VERSION ""

NS_ :

BS_:

BU_: GPU_F MM5_10 PTU GPU TMU_RR TMU_RL TMU_FR TMU_FL DMI SMU_F SMU_R MS6 SW TCU PDU Logger TKU
VAL_TABLE_ BSPD_Emergency 1 "BSPD OK" 0 "Emergancy Open " ;

BO_ 3221225472 VECTOR__INDEPENDENT_SIG_MSG: 0 Vector__XXX
 SG_ HBat_V14 : 0|9@1+ (0.01,0) [0|4.5] "V" Vector__XXX
 SG_ HBat_V05 : 0|9@1+ (0.01,0) [0|4.5] "V" Vector__XXX
 SG_ HBat_V04 : 0|9@1+ (0.01,0) [0|4.5] "V" Vector__XXX
 SG_ HBat_V03 : 0|9@1+ (0.01,0) [0|4.5] "V" Vector__XXX
 SG_ HBat_V13 : 0|9@1+ (0.01,0) [0|4.5] "V" Vector__XXX
 SG_ HBat_V12 : 0|9@1+ (0.01,0) [0|4.5] "V" Vector__XXX
 SG_ HBat_V10 : 0|9@1+ (0.01,0) [0|4.5] "V" Vector__XXX
 SG_ HBat_V11 : 0|9@1+ (0.01,0) [0|4.5] "V" Vector__XXX
 SG_ HBat_V09 : 0|9@1+ (0.01,0) [0|4.5] "V" Vector__XXX
 SG_ HBat_V08 : 0|9@1+ (0.01,0) [0|4.5] "V" Vector__XXX
 SG_ HBat_V07 : 0|9@1+ (0.01,0) [0|4.5] "V" Vector__XXX
 SG_ HBat_V06 : 0|9@1+ (0.01,0) [0|4.5] "V" Vector__XXX
 SG_ HBat_V02 : 0|9@1+ (0.01,0) [0|4.5] "V" Vector__XXX
 SG_ HBat_V01 : 0|9@1+ (0.01,0) [0|4.5] "V" Vector__XXX

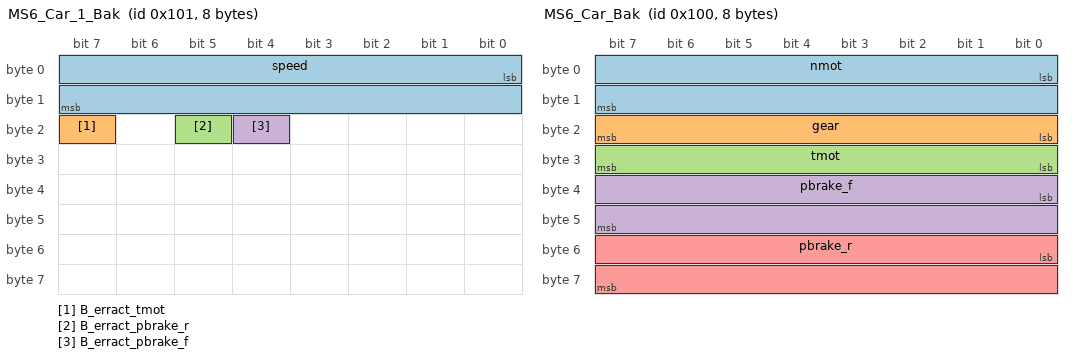
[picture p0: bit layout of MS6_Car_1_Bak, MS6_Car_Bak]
BO_ 257 MS6_Car_1_Bak: 8 MS6
 SG_ speed : 0|16@1+ (0.01,0) [0|400] "km/h"  Logger
 SG_ B_erract_tmot : 23|1@1+ (1,0) [0|1] ""  Logger
 SG_ B_erract_pbrake_r : 21|1@1+ (1,0) [0|1] ""  Logger
 SG_ B_erract_pbrake_f : 20|1@1+ (1,0) [0|1] ""  Logger

BO_ 256 MS6_Car_Bak: 8 MS6
 SG_ nmot : 0|16@1+ (1,0) [0|20000] "rpm"  Logger
 SG_ gear : 16|8@1+ (1,0) [-1|12] ""  Logger
 SG_ tmot : 24|8@1+ (1,-40) [40|120] "°C"  Logger
 SG_ pbrake_f : 32|16@1+ (0.005,0) [0|150] "bar"  Logger
 SG_ pbrake_r : 48|16@1+ (0.005,0) [0|150] "bar"  Logger

BO_ 1120 SMU_R_SpringDeflection: 5 SMU_R
 SG_ SpringDeflectionRR : 16|12@1+ (0.0193,0) [0|79.0335] ""  Logger
 SG_ SpringDeflectionRL : 0|12@1+ (0.0193,0) [0|79.0335] ""  Logger

BO_ 1856 GPU_State: 8 GPU
 SG_ Error_GPU : 8|8@1+ (1,0) [0|0] ""  Logger
 SG_ Alive_GPU : 0|8@1+ (1,0) [0|255] ""  Logger

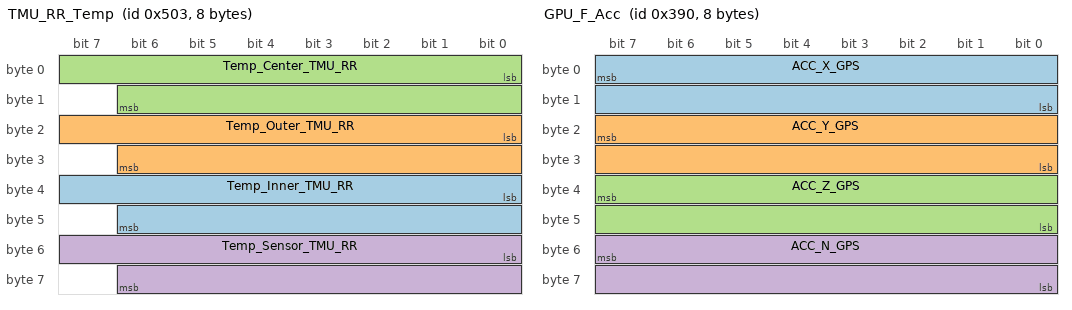
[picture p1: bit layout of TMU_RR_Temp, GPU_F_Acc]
BO_ 1283 TMU_RR_Temp: 8 TMU_RR
 SG_ Temp_Inner_TMU_RR : 32|15@1+ (0.02,-273.15) [-40|85] "°C"  Logger
 SG_ Temp_Outer_TMU_RR : 16|15@1+ (0.02,-273.15) [-40|85] "°C"  Logger
 SG_ Temp_Center_TMU_RR : 0|15@1+ (0.02,-273.15) [-40|85] "°C"  Logger
 SG_ Temp_Sensor_TMU_RR : 48|15@1+ (0.02,-273.15) [-40|125] "°C"  Logger

BO_ 912 GPU_F_Acc: 8 GPU_F
 SG_ ACC_X_GPS : 7|16@0+ (0.0025,-81.9175) [0|0] "m/s"  GPU_F
 SG_ ACC_Y_GPS : 23|16@0+ (0.0025,-81.9175) [0|0] "m/s"  GPU_F
 SG_ ACC_Z_GPS : 39|16@0+ (0.0025,-81.9175) [0|0] "m/s"  GPU_F
 SG_ ACC_N_GPS : 55|16@0+ (0.0025,0) [0|0] "m/s"  GPU_F

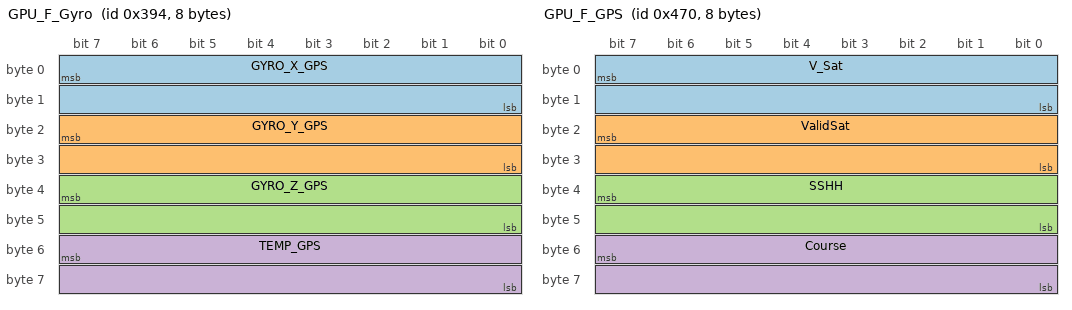
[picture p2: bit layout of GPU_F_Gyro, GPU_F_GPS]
BO_ 916 GPU_F_Gyro: 8 GPU_F
 SG_ GYRO_X_GPS : 7|16@0+ (0.08,-2621.36) [0|0] "deg/s"  GPU_F
 SG_ GYRO_Y_GPS : 23|16@0+ (0.08,-2621.36) [0|0] "deg/s"  GPU_F
 SG_ GYRO_Z_GPS : 39|16@0+ (0.08,-2621.36) [0|0] "deg/s"  GPU_F
 SG_ TEMP_GPS : 55|16@0- (0.1,0) [0|0] "°C"  GPU_F

BO_ 1136 GPU_F_GPS: 8 GPU_F
 SG_ V_Sat : 7|16@0+ (0.01,0) [0|0] "km/h"  GPU_F
 SG_ ValidSat : 23|16@0+ (0.0001,0) [0|0] ""  GPU_F
 SG_ SSHH : 39|16@0+ (0.01,0) [0|0] ""  GPU_F
 SG_ Course : 55|16@0+ (0.01,0) [0|0] "deg"  GPU_F

BO_ 1140 GPU_F_Pos: 8 GPU_F
 SG_ Lat_dez : 7|32@0+ (1E-007,0) [0|0] "deg"  GPU_F
 SG_ Lon_dez : 39|32@0+ (1E-007,0) [0|0] "deg"  GPU_F

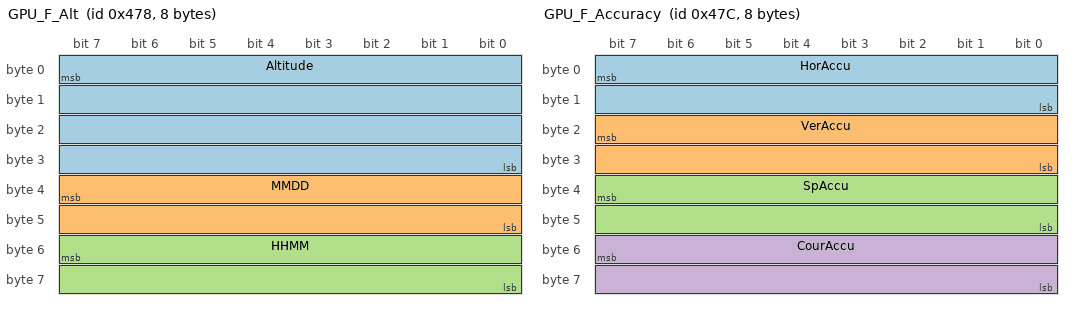
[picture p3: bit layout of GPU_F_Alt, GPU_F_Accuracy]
BO_ 1144 GPU_F_Alt: 8 GPU_F
 SG_ Altitude : 7|32@0+ (0.01,0) [0|0] "m"  GPU_F
 SG_ MMDD : 39|16@0+ (0.01,0) [0|0] ""  GPU_F
 SG_ HHMM : 55|16@0+ (0.01,0) [0|0] ""  GPU_F

BO_ 1148 GPU_F_Accuracy: 8 GPU_F
 SG_ HorAccu : 7|16@0+ (0.001,0) [0|0] "m"  GPU_F
 SG_ VerAccu : 23|16@0+ (0.001,0) [0|0] "m"  GPU_F
 SG_ SpAccu : 39|16@0+ (0.036,0) [0|0] "km/h"  GPU_F
 SG_ CourAccu : 55|16@0+ (0.01,0) [0|0] "deg"  GPU_F

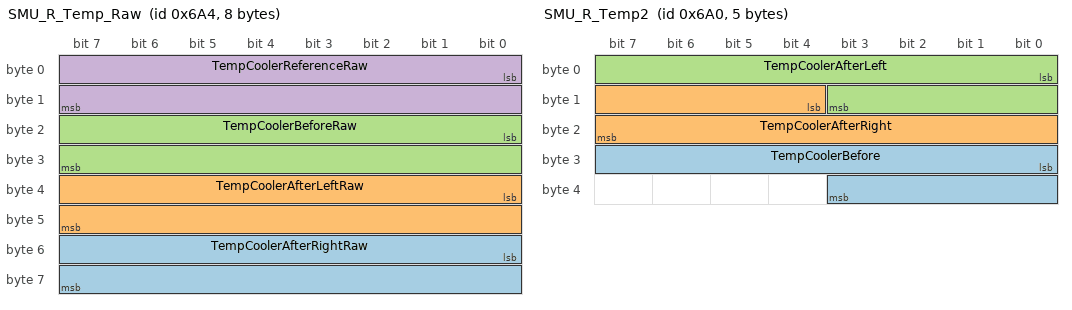
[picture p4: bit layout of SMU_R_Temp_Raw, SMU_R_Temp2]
BO_ 1700 SMU_R_Temp_Raw: 8 SMU_R
 SG_ TempCoolerAfterRightRaw : 48|16@1+ (1,0) [0|65535] ""  Logger
 SG_ TempCoolerAfterLeftRaw : 32|16@1+ (1,0) [0|65535] ""  Logger
 SG_ TempCoolerBeforeRaw : 16|16@1+ (1,0) [0|65535] ""  Logger
 SG_ TempCoolerReferenceRaw : 0|16@1+ (1,0) [0|65535] ""  Logger

BO_ 1696 SMU_R_Temp2: 5 SMU_R
 SG_ TempCoolerBefore : 24|12@1+ (0.1,0) [0|409.5] "°C"  Logger
 SG_ TempCoolerAfterRight : 12|12@1+ (0.1,0) [0|409.5] "°C"  Logger
 SG_ TempCoolerAfterLeft : 0|12@1+ (0.1,0) [0|409.5] "°C"  Logger

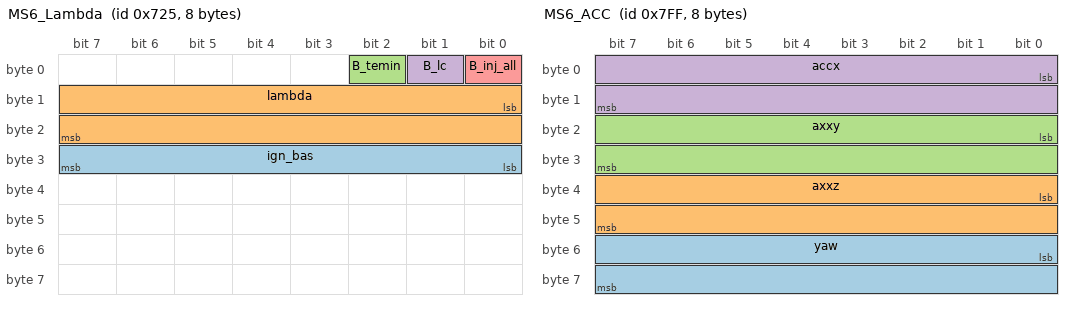
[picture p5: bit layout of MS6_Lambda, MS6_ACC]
BO_ 1829 MS6_Lambda: 8 MS6
 SG_ ign_bas : 24|8@1- (0.5,0) [-30|60] "°CR"  MS6
 SG_ lambda : 8|16@1+ (0.01,0) [0|5] ""  MS6
 SG_ B_temin : 2|1@1+ (1,0) [0|1] ""  Logger
 SG_ B_lc : 1|1@1+ (1,0) [0|1] ""  Logger
 SG_ B_inj_all : 0|1@1+ (1,0) [0|1] ""  Logger

BO_ 1804 MS6_Dist: 8 MS6
 SG_ disttrip : 16|16@1+ (1,0) [0|65535] "km"  Logger
 SG_ ltdist : 0|16@1+ (1,0) [0|65535] "km"  Logger

BO_ 2047 MS6_ACC: 8 MS6
 SG_ yaw : 48|16@1- (0.01,0) [-100|100] "deg/sec"  Logger
 SG_ axxz : 32|16@1- (0.001,0) [-3|3] "g"  Logger
 SG_ axxy : 16|16@1- (0.001,0) [-3|3] "g"  Logger
 SG_ accx : 0|16@1- (0.001,0) [-3|3] "g"  Logger

BO_ 1296 SMU_F_Laptime_Data: 5 SMU_F
 SG_ LapTimePrevious : 8|32@1+ (0.001,0) [0|4294967.295] "s"  DMI,Logger
 SG_ LapCount : 0|8@1+ (1,0) [0|255] ""  DMI,Logger

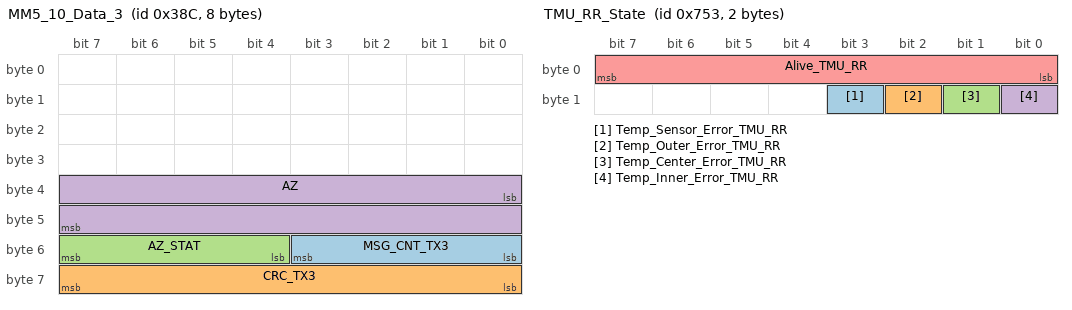
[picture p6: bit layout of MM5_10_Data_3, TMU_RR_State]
BO_ 908 MM5_10_Data_3: 8 MM5_10
 SG_ MSG_CNT_TX3 : 48|4@1+ (1,0) [0|0] "" Vector__XXX
 SG_ CRC_TX3 : 56|8@1+ (1,0) [0|0] "" Vector__XXX
 SG_ AZ_STAT : 52|4@1+ (1,0) [0|0] "" Vector__XXX
 SG_ AZ : 32|16@1+ (0.000127465,-4.1768) [-4.1768|4.1765] "g" Vector__XXX

BO_ 1846 SMU_R_State: 2 SMU_R
 SG_ Error_SMU_R : 8|8@1+ (1,0) [0|255] ""  Logger
 SG_ Alive_SMU_R : 0|8@1+ (1,0) [0|255] ""  Logger

BO_ 1875 TMU_RR_State: 2 TMU_RR
 SG_ Temp_Sensor_Error_TMU_RR : 11|1@1+ (1,0) [0|1] ""  Logger
 SG_ Temp_Outer_Error_TMU_RR : 10|1@1+ (1,0) [0|1] ""  Logger
 SG_ Temp_Center_Error_TMU_RR : 9|1@1+ (1,0) [0|1] ""  Logger
 SG_ Temp_Inner_Error_TMU_RR : 8|1@1+ (1,0) [0|1] ""  Logger
 SG_ Alive_TMU_RR : 0|8@1+ (1,0) [0|255] ""  Logger

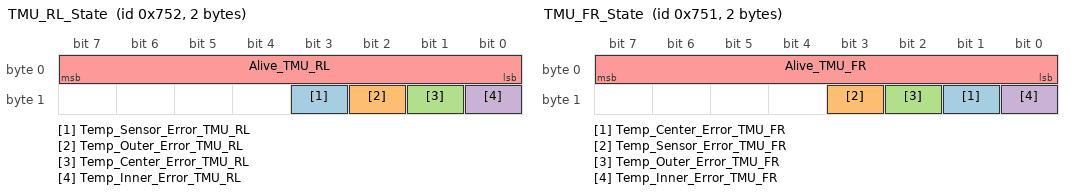
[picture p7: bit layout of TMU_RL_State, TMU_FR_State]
BO_ 1874 TMU_RL_State: 2 TMU_RL
 SG_ Temp_Sensor_Error_TMU_RL : 11|1@1+ (1,0) [0|1] ""  Logger
 SG_ Temp_Outer_Error_TMU_RL : 10|1@1+ (1,0) [0|1] ""  Logger
 SG_ Temp_Center_Error_TMU_RL : 9|1@1+ (1,0) [0|1] ""  Logger
 SG_ Temp_Inner_Error_TMU_RL : 8|1@1+ (1,0) [0|1] ""  Logger
 SG_ Alive_TMU_RL : 0|8@1+ (1,0) [0|255] ""  Logger

BO_ 1873 TMU_FR_State: 2 TMU_FR
 SG_ Temp_Center_Error_TMU_FR : 9|1@1+ (1,0) [0|1] ""  Logger
 SG_ Temp_Sensor_Error_TMU_FR : 11|1@1+ (1,0) [0|1] ""  Logger
 SG_ Temp_Outer_Error_TMU_FR : 10|1@1+ (1,0) [0|1] ""  Logger
 SG_ Temp_Inner_Error_TMU_FR : 8|1@1+ (1,0) [0|1] ""  Logger
 SG_ Alive_TMU_FR : 0|8@1+ (1,0) [0|255] "" Vector__XXX

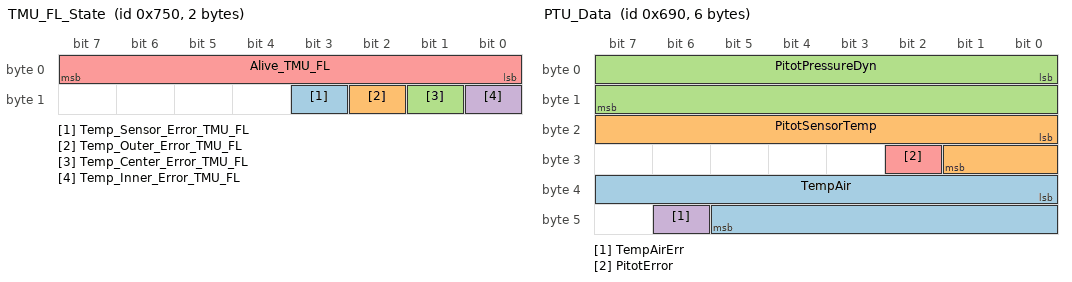
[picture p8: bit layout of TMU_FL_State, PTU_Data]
BO_ 1872 TMU_FL_State: 2 TMU_FL
 SG_ Temp_Sensor_Error_TMU_FL : 11|1@1+ (1,0) [0|1] ""  Logger
 SG_ Temp_Outer_Error_TMU_FL : 10|1@1+ (1,0) [0|1] ""  Logger
 SG_ Temp_Center_Error_TMU_FL : 9|1@1+ (1,0) [0|1] ""  Logger
 SG_ Temp_Inner_Error_TMU_FL : 8|1@1+ (1,0) [0|1] ""  Logger
 SG_ Alive_TMU_FL : 0|8@1+ (1,0) [0|255] ""  Logger

BO_ 1680 PTU_Data: 6 PTU
 SG_ TempAir : 32|14@1- (0.25,0) [-250|1600] "°C"  Logger
 SG_ PitotSensorTemp : 16|10@1+ (0.1956,-50) [-50|150] "°C"  Logger
 SG_ PitotPressureDyn : 0|16@1- (0.2105,0) [-6895|6895] "Pa"  Logger
 SG_ TempAirErr : 46|1@1+ (1,0) [0|1] ""  Logger
 SG_ PitotError : 26|1@1+ (1,0) [0|1] ""  Logger

BO_ 1857 PTU_State: 2 PTU
 SG_ Error_PTU : 8|8@1+ (1,0) [0|255] ""  Logger
 SG_ Alive_PTU : 0|8@1+ (1,0) [0|255] ""  Logger

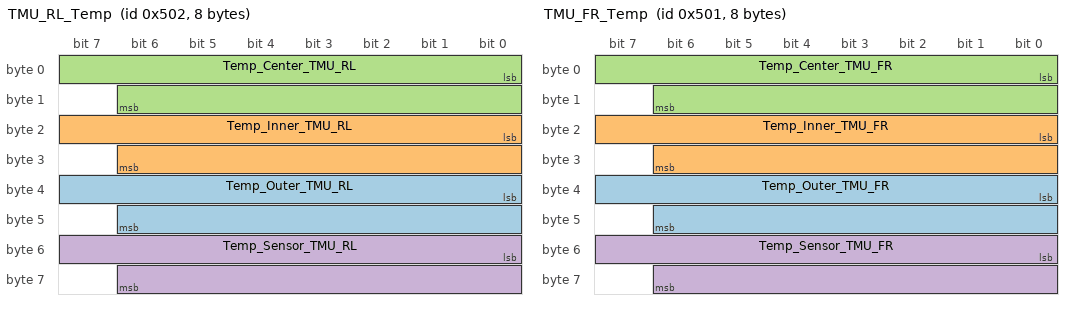
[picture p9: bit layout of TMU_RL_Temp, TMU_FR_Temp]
BO_ 1282 TMU_RL_Temp: 8 TMU_RL
 SG_ Temp_Outer_TMU_RL : 32|15@1+ (0.02,-273.15) [-40|85] "°C"  Logger
 SG_ Temp_Inner_TMU_RL : 16|15@1+ (0.02,-273.15) [-40|85] "°C"  Logger
 SG_ Temp_Center_TMU_RL : 0|15@1+ (0.02,-273.15) [-40|85] "°C"  Logger
 SG_ Temp_Sensor_TMU_RL : 48|15@1+ (0.02,-273.15) [-40|125] "°C"  Logger

BO_ 1281 TMU_FR_Temp: 8 TMU_FR
 SG_ Temp_Outer_TMU_FR : 32|15@1+ (0.02,-273.15) [-40|85] "°C"  Logger
 SG_ Temp_Inner_TMU_FR : 16|15@1+ (0.02,-273.15) [-40|85] "°C"  Logger
 SG_ Temp_Center_TMU_FR : 0|15@1+ (0.02,-273.15) [-40|85] "°C"  Logger
 SG_ Temp_Sensor_TMU_FR : 48|15@1+ (0.02,-273.15) [-40|125] "°C"  Logger

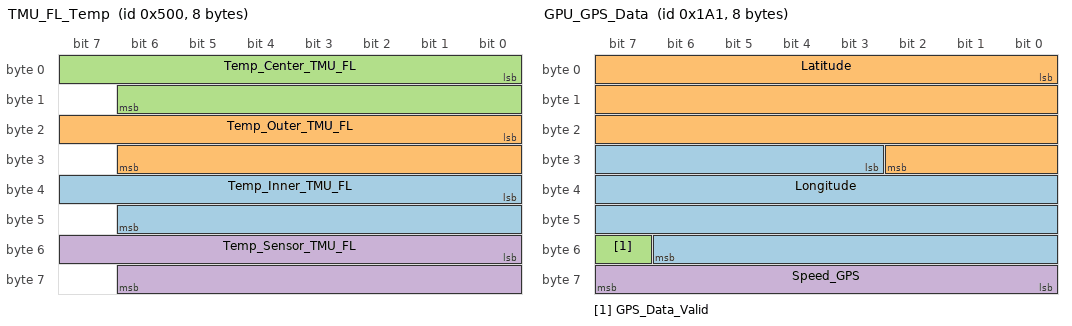
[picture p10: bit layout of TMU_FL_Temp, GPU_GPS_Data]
BO_ 1280 TMU_FL_Temp: 8 TMU_FL
 SG_ Temp_Inner_TMU_FL : 32|15@1+ (0.02,-273.15) [-40|85] "°C"  Logger
 SG_ Temp_Outer_TMU_FL : 16|15@1+ (0.02,-273.15) [-40|85] "°C"  Logger
 SG_ Temp_Center_TMU_FL : 0|15@1+ (0.02,-273.15) [-40|85] "°C"  Logger
 SG_ Temp_Sensor_TMU_FL : 48|15@1+ (0.02,-273.15) [-40|125] "°C"  Logger

BO_ 417 GPU_GPS_Data: 8 GPU
 SG_ Longitude : 27|28@1- (1.6666666667E-006,0) [-180|180] "°"  Logger
 SG_ Latitude : 0|27@1- (1.6666666667E-006,0) [-90|90] "°"  Logger
 SG_ GPS_Data_Valid : 55|1@1+ (1,0) [0|1] ""  Logger
 SG_ Speed_GPS : 56|8@1- (1,0) [-128|127] "km/h"  Logger

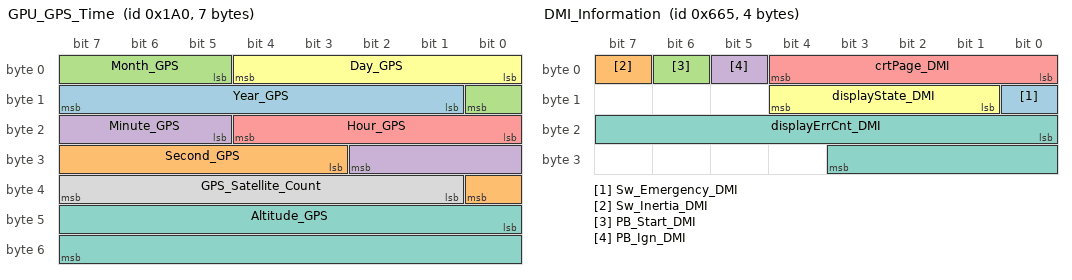
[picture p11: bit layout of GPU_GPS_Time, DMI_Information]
BO_ 416 GPU_GPS_Time: 7 GPU
 SG_ Year_GPS : 9|7@1+ (1,0) [0|99] ""  Logger
 SG_ Second_GPS : 27|6@1+ (1,0) [0|59] ""  Logger
 SG_ Month_GPS : 5|4@1+ (1,0) [0|12] ""  Logger
 SG_ Minute_GPS : 21|6@1+ (1,0) [0|59] ""  Logger
 SG_ Hour_GPS : 16|5@1+ (1,0) [0|23] ""  Logger
 SG_ Day_GPS : 0|5@1+ (1,0) [0|31] ""  Logger
 SG_ Altitude_GPS : 40|16@1+ (1,-999) [-999|3276.7] ""  Logger
 SG_ GPS_Satellite_Count : 33|7@1+ (1,0) [0|127] ""  Logger

BO_ 1637 DMI_Information: 4 DMI
 SG_ Sw_Emergency_DMI : 8|1@1+ (1,0) [0|1] ""  Logger
 SG_ Sw_Inertia_DMI : 7|1@1+ (1,0) [0|1] ""  Logger
 SG_ PB_Start_DMI : 6|1@1+ (1,0) [0|1] ""  Logger
 SG_ PB_Ign_DMI : 5|1@1+ (1,0) [0|1] ""  Logger
 SG_ crtPage_DMI : 0|5@1+ (1,0) [0|31] ""  Logger
 SG_ displayState_DMI : 9|4@1+ (1,0) [0|15] "" Vector__XXX
 SG_ displayErrCnt_DMI : 16|12@1+ (1,0) [0|4095] "" Vector__XXX

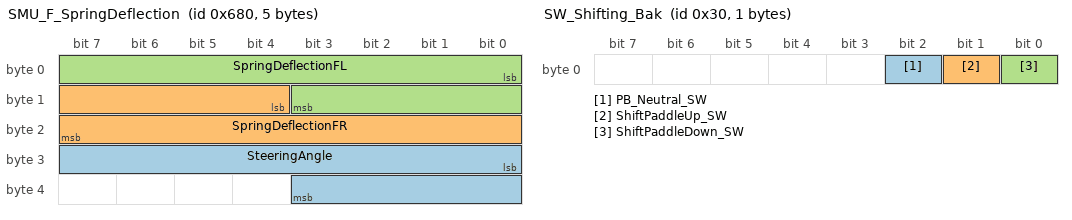
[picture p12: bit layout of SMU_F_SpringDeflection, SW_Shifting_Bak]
BO_ 1664 SMU_F_SpringDeflection: 5 SMU_F
 SG_ SteeringAngle : 24|12@1+ (0.24415,-233.33) [-233.33|766.46425] ""  Logger
 SG_ SpringDeflectionFR : 12|12@1+ (0.018315018,0) [0|74.99999871] ""  Logger
 SG_ SpringDeflectionFL : 0|12@1+ (0.018315018,0) [0|74.99999871] ""  Logger

BO_ 48 SW_Shifting_Bak: 1 SW
 SG_ PB_Neutral_SW : 2|1@1+ (1,0) [0|1] ""  Logger
 SG_ ShiftPaddleUp_SW : 1|1@1+ (1,0) [0|1] ""  Logger,TCU
 SG_ ShiftPaddleDown_SW : 0|1@1+ (1,0) [0|1] ""  Logger,TCU

BO_ 64 SW_Clutch_Bak: 2 SW
 SG_ ClutchPercentRight_SW : 8|8@1+ (0.3922,0) [0|100] "%"  Logger,TCU
 SG_ ClutchPercentLeft_SW : 0|8@1+ (0.3922,0) [0|100] "%"  Logger,TCU

BO_ 1845 DMI_State: 2 DMI
 SG_ Error_DMI : 8|8@1+ (1,0) [0|0] ""  Logger
 SG_ Alive_DMI : 0|8@1+ (1,0) [0|255] ""  Logger

BO_ 1844 SMU_F_State: 2 SMU_F
 SG_ Error_SMU_F : 8|8@1+ (1,0) [0|0] ""  Logger
 SG_ Alive_SMU_F : 0|8@1+ (1,0) [0|255] ""  Logger

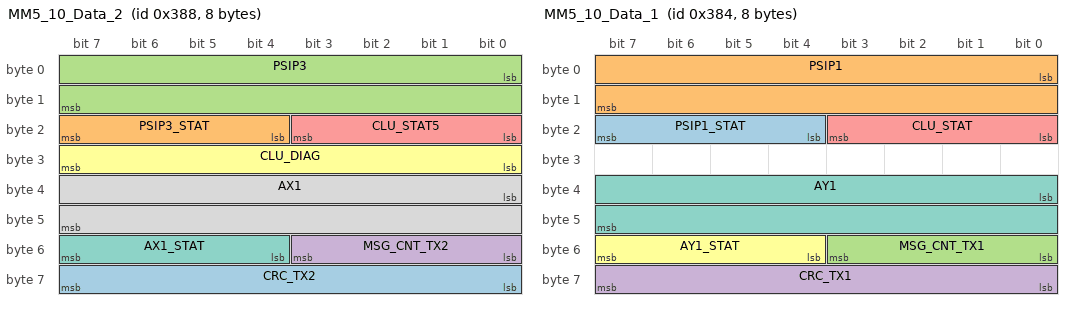
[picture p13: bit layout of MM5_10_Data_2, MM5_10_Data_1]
BO_ 904 MM5_10_Data_2: 8 MM5_10
 SG_ CRC_TX2 : 56|8@1+ (1,0) [0|0] "" Vector__XXX
 SG_ PSIP3_STAT : 20|4@1+ (1,0) [0|0] "" Vector__XXX
 SG_ PSIP3 : 0|16@1+ (0.005,-163.84) [-163.84|163.835] "°/s" Vector__XXX
 SG_ MSG_CNT_TX2 : 48|4@1+ (1,0) [0|0] "" Vector__XXX
 SG_ CLU_STAT5 : 16|4@1+ (1,0) [0|0] "" Vector__XXX
 SG_ CLU_DIAG : 24|8@1+ (1,0) [0|0] "" Vector__XXX
 SG_ AX1_STAT : 52|4@1+ (1,0) [0|0] "" Vector__XXX
 SG_ AX1 : 32|16@1+ (0.000127465,-4.1768) [-4.1768|4.1765] "g" Vector__XXX

BO_ 900 MM5_10_Data_1: 8 MM5_10
 SG_ PSIP1_STAT : 20|4@1+ (1,0) [0|0] "" Vector__XXX
 SG_ PSIP1 : 0|16@1+ (0.005,-163.84) [-163.84|163.83] "°/s" Vector__XXX
 SG_ MSG_CNT_TX1 : 48|4@1+ (1,0) [0|0] "" Vector__XXX
 SG_ CRC_TX1 : 56|8@1+ (1,0) [0|0] "" Vector__XXX
 SG_ CLU_STAT : 16|4@1+ (1,0) [0|0] "" Vector__XXX
 SG_ AY1_STAT : 52|4@1+ (1,0) [0|0] "" Vector__XXX
 SG_ AY1 : 32|16@1+ (0.000127465,-4.1768) [-4.1768|4.1765] "g" Vector__XXX

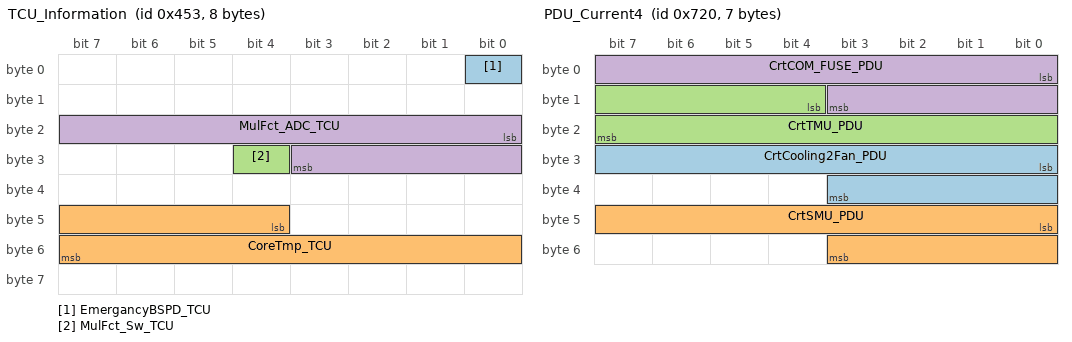
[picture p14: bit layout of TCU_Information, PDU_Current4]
BO_ 1107 TCU_Information: 8 TCU
 SG_ EmergancyBSPD_TCU : 0|1@1+ (1,0) [0|1] "" Vector__XXX
 SG_ CoreTmp_TCU : 44|12@1+ (1,0) [0|0] "°C"  Logger
 SG_ MulFct_Sw_TCU : 28|1@1+ (1,0) [0|1] ""  Logger
 SG_ MulFct_ADC_TCU : 16|12@1+ (1,0) [0|4095] ""  Logger

BO_ 1840 TCU_State: 4 TCU
 SG_ Alive_TCU : 16|8@1+ (1,0) [0|255] ""  Logger
 SG_ Error_TCU : 8|8@1+ (1,0) [0|0] ""  Logger

BO_ 1824 PDU_Current4: 7 PDU
 SG_ CrtCooling2Fan_PDU : 24|12@1+ (13,0) [0|50000] "mA"  Logger
 SG_ CrtSMU_PDU : 40|12@1+ (13,0) [0|50000] "mA" Vector__XXX
 SG_ CrtTMU_PDU : 12|12@1+ (13,0) [0|50000] "mA"  Logger
 SG_ CrtCOM_FUSE_PDU : 0|12@1+ (13,0) [0|50000] "mA"  Logger

BO_ 1842 PDU_State: 2 PDU
 SG_ Error_PDU : 8|8@1+ (1,0) [0|0] ""  Logger
 SG_ Alive_PDU : 0|8@1+ (1,0) [0|255] ""  Logger

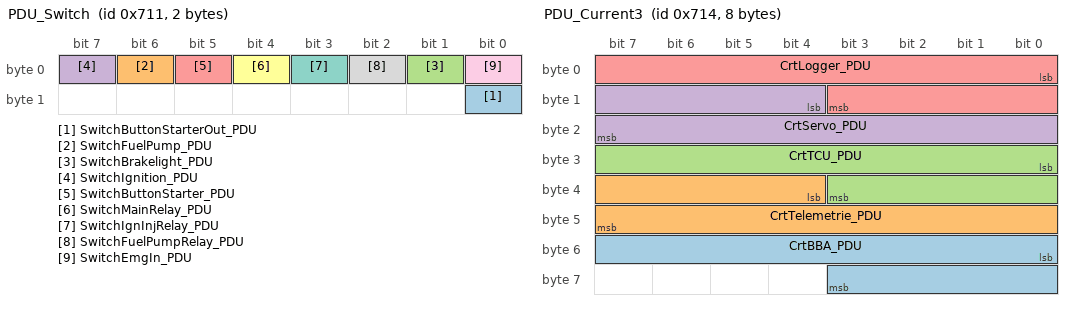
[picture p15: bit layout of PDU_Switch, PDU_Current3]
BO_ 1809 PDU_Switch: 2 PDU
 SG_ SwitchButtonStarterOut_PDU : 8|1@1+ (1,0) [0|1] "Bit"  Logger
 SG_ SwitchFuelPump_PDU : 6|1@1+ (1,0) [0|1] "Bit"  Logger
 SG_ SwitchBrakelight_PDU : 1|1@1+ (1,0) [0|1] "Bit"  Logger
 SG_ SwitchIgnition_PDU : 7|1@1+ (1,0) [0|1] "Bit"  Logger
 SG_ SwitchButtonStarter_PDU : 5|1@1+ (1,0) [0|1] "Bit"  Logger
 SG_ SwitchMainRelay_PDU : 4|1@1+ (1,0) [0|1] "Bit"  Logger
 SG_ SwitchIgnInjRelay_PDU : 3|1@1+ (1,0) [0|1] "Bit"  Logger
 SG_ SwitchFuelPumpRelay_PDU : 2|1@1+ (1,0) [0|1] "Bit"  Logger
 SG_ SwitchEmgIn_PDU : 0|1@1+ (1,0) [0|1] "Bit"  Logger

BO_ 1808 PDU_Fuses: 3 PDU
 SG_ FuseCooling2_PDU : 22|1@1+ (1,0) [0|1] "Bit"  Logger
 SG_ FuseSMU_PDU : 23|1@1+ (1,0) [0|1] "Bit" Vector__XXX
 SG_ FuseBBA_PDU : 14|1@1+ (1,0) [0|1] "Bit"  Logger
 SG_ FuseBSPD_PDU : 13|1@1+ (1,0) [0|1] "Bit"  Logger
 SG_ FuseSwitch_PDU : 3|1@1+ (1,0) [0|1] "Bit"  Logger
 SG_ FuseWaterpump_PDU : 21|1@1+ (1,0) [0|1] "Bit"  Logger
 SG_ FuseTMU_PDU : 20|1@1+ (1,0) [0|1] "Bit"  Logger
 SG_ FuseTelemetry_PDU : 19|1@1+ (1,0) [0|1] "Bit"  Logger
 SG_ FuseTCU_PDU : 18|1@1+ (1,0) [0|1] "Bit"  Logger
 SG_ FuseCom_Fuse_PDU : 17|1@1+ (1,0) [0|1] "Bit"  Logger
 SG_ FuseSW_PDU : 16|1@1+ (1,0) [0|1] "Bit"  Logger
 SG_ FuseServo_PDU : 15|1@1+ (1,0) [0|1] "Bit"  Logger
 SG_ RelayFuelPump_PDU : 12|1@1+ (1,0) [0|1] "Bit"  Logger
 SG_ FuseECUPower_PDU : 11|1@1+ (1,0) [0|1] "Bit"  Logger
 SG_ FuseMonoFan_PDU : 10|1@1+ (1,0) [0|1] "Bit"  Logger
 SG_ FuseLogger_PDU : 9|1@1+ (1,0) [0|1] "Bit"  Logger
 SG_ FuseLambda_PDU : 8|1@1+ (1,0) [0|1] "Bit"  Logger
 SG_ FuseInjection_PDU : 7|1@1+ (1,0) [0|1] "Bit"  Logger
 SG_ FuseIgnition_PDU : 6|1@1+ (1,0) [0|1] "Bit"  Logger
 SG_ FuseFuelpump_PDU : 5|1@1+ (1,0) [0|1] "Bit"  Logger
 SG_ FuseEmgOut_PDU : 4|1@1+ (1,0) [0|1] "Bit"  Logger
 SG_ FuseDMI_PDU : 2|1@1+ (1,0) [0|1] "Bit"  Logger
 SG_ FuseCoolingFan_PDU : 1|1@1+ (1,0) [0|1] "Bit"  Logger
 SG_ FuseBrakelight_PDU : 0|1@1+ (1,0) [0|1] "Bit"  Logger

BO_ 1812 PDU_Current3: 8 PDU
 SG_ CrtBBA_PDU : 48|12@1+ (13,0) [0|50000] "mA"  Logger
 SG_ CrtTelemetrie_PDU : 36|12@1+ (13,0) [0|50000] "mA"  Logger
 SG_ CrtTCU_PDU : 24|12@1+ (13,0) [0|50000] "mA"  Logger
 SG_ CrtServo_PDU : 12|12@1+ (13,0) [0|50000] "mA"  Logger
 SG_ CrtLogger_PDU : 0|12@1+ (13,0) [0|50000] "mA"  Logger

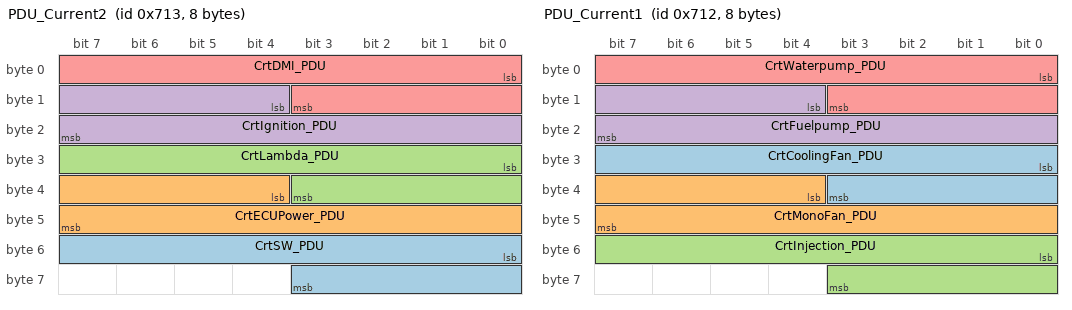
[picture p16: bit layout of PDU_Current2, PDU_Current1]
BO_ 1811 PDU_Current2: 8 PDU
 SG_ CrtSW_PDU : 48|12@1+ (13,0) [0|50000] "mA"  Logger
 SG_ CrtECUPower_PDU : 36|12@1+ (13,0) [0|50000] "mA"  Logger
 SG_ CrtLambda_PDU : 24|12@1+ (13,0) [0|50000] "mA"  Logger
 SG_ CrtIgnition_PDU : 12|12@1+ (13,0) [0|50000] "mA"  Logger
 SG_ CrtDMI_PDU : 0|12@1+ (13,0) [0|50000] "mA"  Logger

BO_ 1810 PDU_Current1: 8 PDU
 SG_ CrtCoolingFan_PDU : 24|12@1+ (13,0) [0|50000] "mA"  Logger
 SG_ CrtMonoFan_PDU : 36|12@1+ (13,0) [0|50000] "mA"  Logger
 SG_ CrtInjection_PDU : 48|12@1+ (13,0) [0|50000] "mA"  Logger
 SG_ CrtFuelpump_PDU : 12|12@1+ (13,0) [0|50000] "mA"  Logger
 SG_ CrtWaterpump_PDU : 0|12@1+ (13,0) [0|50000] "mA"  Logger

BO_ 1536 TKU_State: 3 TKU
 SG_ Error_TKU : 8|8@1+ (1,0) [0|0] "" Vector__XXX
 SG_ Alive_TKU : 0|8@1+ (1,0) [0|255] "" Vector__XXX

BO_ 1044 TKU_Temp2: 8 TKU
 SG_ TmpTypT5Err_TKU : 14|1@1+ (1,0) [0|1] "" Vector__XXX
 SG_ TmpTypT5_TKU : 0|14@1- (0.25,0) [-250|400] "" Vector__XXX

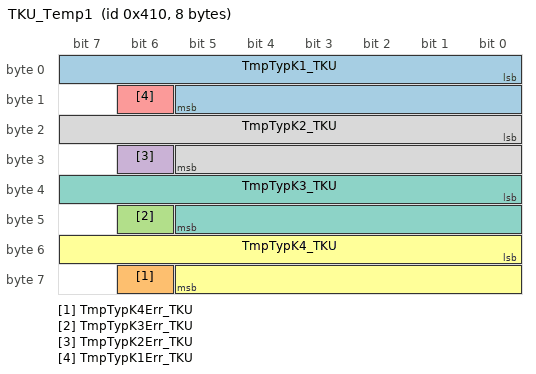
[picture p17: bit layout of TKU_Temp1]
BO_ 1040 TKU_Temp1: 8 TKU
 SG_ TmpTypK1_TKU : 0|14@1- (0.25,0) [-250|1600] ""  Logger
 SG_ TmpTypK4Err_TKU : 62|1@1+ (1,0) [0|1] "" Vector__XXX
 SG_ TmpTypK3Err_TKU : 46|1@1+ (1,0) [0|1] "" Vector__XXX
 SG_ TmpTypK2Err_TKU : 30|1@1+ (1,0) [0|1] "" Vector__XXX
 SG_ TmpTypK1Err_TKU : 14|1@1+ (1,0) [0|1] "" Vector__XXX
 SG_ TmpTypK4_TKU : 48|14@1- (0.25,0) [-250|1600] "" Vector__XXX
 SG_ TmpTypK3_TKU : 32|14@1- (0.25,0) [-250|1600] "" Vector__XXX
 SG_ TmpTypK2_TKU : 16|14@1- (0.25,0) [-250|1600] "" Vector__XXX

CM_ BO_ 3221225472 "This is a message for not used signals, created by Vector CANdb++ DBC OLE DB Provider.";
CM_ SG_ 257 speed "car speed";
CM_ SG_ 257 B_erract_tmot "condition error detect for tmot1, not debounced";
CM_ SG_ 257 B_erract_pbrake_r "condition error detect for pbrake_r, not debounced";
CM_ SG_ 257 B_erract_pbrake_f "condition error detect for pbrake_f, not debounced";
CM_ SG_ 256 nmot "engine speed";
CM_ SG_ 256 gear "selected gear";
CM_ SG_ 256 tmot "engine temperature";
CM_ SG_ 256 pbrake_f "brake pressure front ";
CM_ SG_ 256 pbrake_r "brake pressure rear";
CM_ SG_ 912 ACC_X_GPS "Rotated Acc_x value";
CM_ SG_ 912 ACC_Y_GPS "Rotated Acc_y value";
CM_ SG_ 912 ACC_Z_GPS "Rotated Acc_z value";
CM_ SG_ 912 ACC_N_GPS "Rotated Acc_N value";
CM_ SG_ 916 GYRO_X_GPS "Rotated Gyro_x value";
CM_ SG_ 916 GYRO_Y_GPS "Rotated Gyro_y value";
CM_ SG_ 916 GYRO_Z_GPS "Rotated Gyro_z value";
CM_ SG_ 916 TEMP_GPS "Temperature IMU";
CM_ SG_ 1136 V_Sat "GPS speed over ground";
CM_ SG_ 1136 ValidSat "Visible satellites";
CM_ SG_ 1136 SSHH "Seconds:Hundredth";
CM_ SG_ 1136 Course "vehicle moving direction";
CM_ SG_ 1140 Lat_dez "Position in dezimal degree";
CM_ SG_ 1140 Lon_dez "Position in dezimal degree";
CM_ SG_ 1144 Altitude "m above sea level";
CM_ SG_ 1144 MMDD "Month:Day";
CM_ SG_ 1144 HHMM "Hour:Minute";
CM_ SG_ 1148 HorAccu "accuracy horizontal position";
CM_ SG_ 1148 VerAccu "accuracy vertical position";
CM_ SG_ 1148 SpAccu "accuracy of speed";
CM_ SG_ 1148 CourAccu "accuracy of course";
CM_ SG_ 1829 ign_bas "basic ignition angle";
CM_ SG_ 1829 lambda "Lambda actual value";
CM_ SG_ 1829 B_temin "condition minimum effective injection time";
CM_ SG_ 1829 B_lc "condition Lambda control on";
CM_ SG_ 1829 B_inj_all "condition all injections active";
CM_ SG_ 1804 disttrip "distance covered over trip, kilometer counter";
CM_ SG_ 1804 ltdist "distance covered over lifetime, kilometer counter";
CM_ SG_ 2047 yaw "yaw rate";
CM_ SG_ 2047 axxz "vertical acceleration";
CM_ SG_ 2047 axxy "lateral acceleration";
CM_ SG_ 2047 accx "longitudinal acceleration";
CM_ SG_ 1296 LapTimePrevious "delta time of the last lap";
CM_ SG_ 1296 LapCount "current lap count";
CM_ SG_ 1680 TempAir "air temperature measured by a thermocouple at the pitot tube";
CM_ SG_ 1680 PitotSensorTemp "temperature measured at the pressure sensor";
CM_ SG_ 1680 PitotPressureDyn "dynamic pressure measured between the total pressure of the pitot tube and the static pressure";
BA_DEF_ SG_  "GenSigStartValue" FLOAT 0 0;
BA_DEF_ BO_  "GenMsgSendType2" ENUM  "Zyklisch","Ereignisgesteuert","dummy","Auf Anfrage";
BA_DEF_ BO_  "GenMsgCycleTimeActive" INT 1 100;
BA_DEF_ BO_  "GenMsgCycleTimeFast" INT 1 50;
BA_DEF_ BO_  "GenMsgFastOnStart" INT 10 500;
BA_DEF_ BO_  "GenMsgDelayTime" INT 10 500;
BA_DEF_ BO_  "GenSigSendType" ENUM  "Cyclic","OnWrite","OnChange";
BA_DEF_ BO_  "GenMsgSendType" ENUM  "cyclic","spontaneous","adaptive";
BA_DEF_ BO_  "GenMsgCycleTime" INT 5 1000;
BA_DEF_ BU_  "MessageManagerUsed" ENUM  "no","yes";
BA_DEF_  "Manufacturer" ENUM  "DBAG","VAG","BMWAG";
BA_DEF_  "BusType" STRING ;
BA_DEF_DEF_  "GenSigStartValue" 0;
BA_DEF_DEF_  "GenMsgSendType2" "Zyklisch";
BA_DEF_DEF_  "GenMsgCycleTimeActive" 10;
BA_DEF_DEF_  "GenMsgCycleTimeFast" 10;
BA_DEF_DEF_  "GenMsgFastOnStart" 10;
BA_DEF_DEF_  "GenMsgDelayTime" 10;
BA_DEF_DEF_  "GenSigSendType" "Cyclic";
BA_DEF_DEF_  "GenMsgSendType" "cyclic";
BA_DEF_DEF_  "GenMsgCycleTime" 100;
BA_DEF_DEF_  "MessageManagerUsed" "yes";
BA_DEF_DEF_  "Manufacturer" "BMWAG";
BA_DEF_DEF_  "BusType" "CAN";
BA_ "GenMsgCycleTime" BO_ 257 10;
BA_ "GenMsgCycleTime" BO_ 256 10;
BA_ "GenMsgCycleTimeFast" BO_ 1120 5;
BA_ "GenMsgCycleTime" BO_ 1120 5;
BA_ "GenMsgCycleTime" BO_ 1283 500;
BA_ "GenMsgCycleTime" BO_ 912 5;
BA_ "GenMsgCycleTime" BO_ 916 5;
BA_ "GenMsgCycleTime" BO_ 1136 40;
BA_ "GenMsgCycleTime" BO_ 1140 40;
BA_ "GenMsgCycleTime" BO_ 1144 40;
BA_ "GenMsgCycleTime" BO_ 1148 40;
BA_ "GenMsgCycleTime" BO_ 1700 1000;
BA_ "GenMsgCycleTime" BO_ 1696 500;
BA_ "GenMsgCycleTime" BO_ 1804 1000;
BA_ "GenMsgCycleTime" BO_ 2047 10;
BA_ "GenMsgCycleTime" BO_ 1296 500;
BA_ "GenMsgCycleTime" BO_ 908 5;
BA_ "GenMsgCycleTime" BO_ 1846 500;
BA_ "GenMsgCycleTime" BO_ 1875 500;
BA_ "GenMsgCycleTime" BO_ 1874 500;
BA_ "GenMsgCycleTime" BO_ 1873 500;
BA_ "GenMsgCycleTime" BO_ 1872 500;
BA_ "GenMsgCycleTime" BO_ 1282 500;
BA_ "GenMsgCycleTime" BO_ 1281 500;
BA_ "GenMsgCycleTime" BO_ 1280 500;
BA_ "GenMsgCycleTime" BO_ 417 10;
BA_ "GenMsgCycleTime" BO_ 416 10;
BA_ "GenMsgCycleTimeFast" BO_ 1664 1;
BA_ "GenMsgCycleTime" BO_ 1664 5;
BA_ "GenMsgCycleTime" BO_ 64 10;
BA_ "GenMsgCycleTime" BO_ 1845 500;
BA_ "GenMsgCycleTime" BO_ 1844 500;
BA_ "GenMsgCycleTime" BO_ 904 5;
BA_ "GenMsgCycleTime" BO_ 900 5;
BA_ "GenMsgCycleTime" BO_ 1840 500;
BA_ "GenMsgCycleTime" BO_ 1842 500;
BA_ "GenMsgCycleTime" BO_ 1808 500;
BA_ "GenMsgCycleTime" BO_ 1536 500;
BA_ "GenSigStartValue" SG_ 256 tmot 80;
BA_ "GenSigStartValue" SG_ 1283 Temp_Inner_TMU_RR 13657.5;
BA_ "GenSigStartValue" SG_ 1283 Temp_Outer_TMU_RR 13657.5;
BA_ "GenSigStartValue" SG_ 1283 Temp_Center_TMU_RR 13657.5;
BA_ "GenSigStartValue" SG_ 1283 Temp_Sensor_TMU_RR 13657.5;
BA_ "GenSigStartValue" SG_ 1680 PitotSensorTemp 255.623721881391;
BA_ "GenSigStartValue" SG_ 1680 PitotError 1;
BA_ "GenSigStartValue" SG_ 1282 Temp_Outer_TMU_RL 13657.5;
BA_ "GenSigStartValue" SG_ 1282 Temp_Inner_TMU_RL 13657.5;
BA_ "GenSigStartValue" SG_ 1282 Temp_Center_TMU_RL 13657.5;
BA_ "GenSigStartValue" SG_ 1282 Temp_Sensor_TMU_RL 13657.5;
BA_ "GenSigStartValue" SG_ 1281 Temp_Outer_TMU_FR 13657.5;
BA_ "GenSigStartValue" SG_ 1281 Temp_Inner_TMU_FR 13657.5;
BA_ "GenSigStartValue" SG_ 1281 Temp_Center_TMU_FR 13657.5;
BA_ "GenSigStartValue" SG_ 1281 Temp_Sensor_TMU_FR 13657.5;
BA_ "GenSigStartValue" SG_ 1280 Temp_Inner_TMU_FL 13657.5;
BA_ "GenSigStartValue" SG_ 1280 Temp_Outer_TMU_FL 13657.5;
BA_ "GenSigStartValue" SG_ 1280 Temp_Center_TMU_FL 13657.5;
BA_ "GenSigStartValue" SG_ 1280 Temp_Sensor_TMU_FL 13657.5;
BA_ "GenSigStartValue" SG_ 416 Altitude_GPS 999;
BA_ "GenSigStartValue" SG_ 1664 SteeringAngle 108.314564153574;
VAL_ 1107 EmergancyBSPD_TCU 1 "BSPD OK" 0 "Emergancy Open " ;
